# CC27x0 register map
File version: 1.0
CPU: CM4 r0p4, little endian, no MPU, no FPU, VTOR, 3 interrupt priority bits
Registers are 32-bit, read-write, reset 0x0 unless marked. A register's access mark holds for its fields unless they carry their own. Offsets are from the block's base; [hi:lo] are bit positions; {n}, {i} and the like mark numbered series; 'fields as' and 'values as' point back to an identical list.

## LRFDMDM (part 1 of 2)
Base 0x40082000
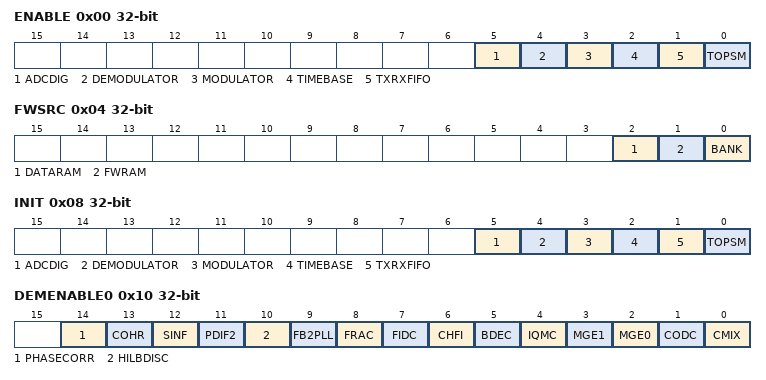
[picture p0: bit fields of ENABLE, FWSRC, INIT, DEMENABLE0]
0x00 ENABLE — Internal. Only to be used through TI provided API.
  [all] fields
    1=EN (Internal. Only to be used through TI provided API.); 0=DIS (Internal. Only to be used through TI provided API.)
  [5] ADCDIG — Internal. Only to be used through TI provided API.
  [4] DEMODULATOR — Internal. Only to be used through TI provided API.
  [3] MODULATOR — Internal. Only to be used through TI provided API.
  [2] TIMEBASE — Internal. Only to be used through TI provided API.
  [1] TXRXFIFO — Internal. Only to be used through TI provided API.
  [0] TOPSM — Internal. Only to be used through TI provided API.
0x04 FWSRC — Internal. Only to be used through TI provided API.
  [2] DATARAM — Internal. Only to be used through TI provided API.
    1=S2RRAM (Internal. Only to be used through TI provided API.); 0=MDMRAM (Internal. Only to be used through TI provided API.)
  [1] FWRAM — Internal. Only to be used through TI provided API.
    values as DATARAM
  [0] BANK — Internal. Only to be used through TI provided API.
    1=ONE (Internal. Only to be used through TI provided API.); 0=ZERO (Internal. Only to be used through TI provided API.)
0x08 INIT wo — Internal. Only to be used through TI provided API.
  [all] fields
    1=RESET (Internal. Only to be used through TI provided API.); 0=NO_EFFECT (Internal. Only to be used through TI provided API.)
  [5] ADCDIG — Internal. Only to be used through TI provided API.
  [4] DEMODULATOR — Internal. Only to be used through TI provided API.
  [3] MODULATOR — Internal. Only to be used through TI provided API.
  [2] TIMEBASE — Internal. Only to be used through TI provided API.
  [1] TXRXFIFO — Internal. Only to be used through TI provided API.
  [0] TOPSM — Internal. Only to be used through TI provided API.
0x10 DEMENABLE0 — Internal. Only to be used through TI provided API.
  [14] PHASECORR — Internal. Only to be used through TI provided API.
  [13] COHR — Internal. Only to be used through TI provided API.
  [12] SINF — Internal. Only to be used through TI provided API.
  [11] PDIF2 — Internal. Only to be used through TI provided API.
  [10] HILBDISC — Internal. Only to be used through TI provided API.
  [9] FB2PLL — Internal. Only to be used through TI provided API.
  [8] FRAC — Internal. Only to be used through TI provided API.
    values as the fields of ENABLE
  [7] FIDC — Internal. Only to be used through TI provided API.
    values as the fields of ENABLE
  [6] CHFI — Internal. Only to be used through TI provided API.
    values as the fields of ENABLE
  [5] BDEC — Internal. Only to be used through TI provided API.
    values as the fields of ENABLE
  [4] IQMC — Internal. Only to be used through TI provided API.
    values as the fields of ENABLE
  [3] MGE1 — Internal. Only to be used through TI provided API.
    values as the fields of ENABLE
  [2] MGE0 — Internal. Only to be used through TI provided API.
    values as the fields of ENABLE
  [1] CODC — Internal. Only to be used through TI provided API.
    values as the fields of ENABLE
  [0] CMIX — Internal. Only to be used through TI provided API.
    values as the fields of ENABLE
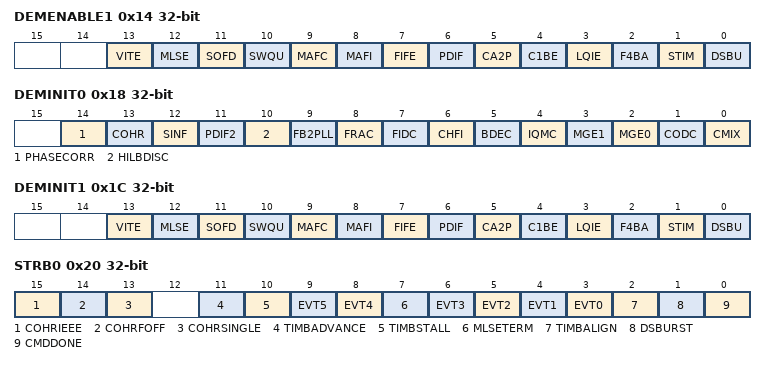
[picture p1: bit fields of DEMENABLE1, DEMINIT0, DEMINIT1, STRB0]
0x14 DEMENABLE1 — Internal. Only to be used through TI provided API.
  [all] fields
    values as the fields of ENABLE
  [13] VITE — Internal. Only to be used through TI provided API.
  [12] MLSE — Internal. Only to be used through TI provided API.
  [11] SOFD — Internal. Only to be used through TI provided API.
  [10] SWQU — Internal. Only to be used through TI provided API.
  [9] MAFC — Internal. Only to be used through TI provided API.
  [8] MAFI — Internal. Only to be used through TI provided API.
  [7] FIFE — Internal. Only to be used through TI provided API.
  [6] PDIF — Internal. Only to be used through TI provided API.
  [5] CA2P — Internal. Only to be used through TI provided API.
  [4] C1BE — Internal. Only to be used through TI provided API.
  [3] LQIE — Internal. Only to be used through TI provided API.
  [2] F4BA — Internal. Only to be used through TI provided API.
  [1] STIM — Internal. Only to be used through TI provided API.
  [0] DSBU — Internal. Only to be used through TI provided API.
0x18 DEMINIT0 wo — Internal. Only to be used through TI provided API.
  [14] PHASECORR — Internal. Only to be used through TI provided API.
  [13] COHR — Internal. Only to be used through TI provided API.
  [12] SINF — Internal. Only to be used through TI provided API.
  [11] PDIF2 — Internal. Only to be used through TI provided API.
  [10] HILBDISC — Internal. Only to be used through TI provided API.
  [9] FB2PLL — Internal. Only to be used through TI provided API.
  [8] FRAC — Internal. Only to be used through TI provided API.
    values as the fields of INIT
  [7] FIDC — Internal. Only to be used through TI provided API.
    values as the fields of INIT
  [6] CHFI — Internal. Only to be used through TI provided API.
    values as the fields of INIT
  [5] BDEC — Internal. Only to be used through TI provided API.
    values as the fields of INIT
  [4] IQMC — Internal. Only to be used through TI provided API.
    values as the fields of INIT
  [3] MGE1 — Internal. Only to be used through TI provided API.
    values as the fields of INIT
  [2] MGE0 — Internal. Only to be used through TI provided API.
    values as the fields of INIT
  [1] CODC — Internal. Only to be used through TI provided API.
    values as the fields of INIT
  [0] CMIX — Internal. Only to be used through TI provided API.
    values as the fields of INIT
0x1C DEMINIT1 wo — Internal. Only to be used through TI provided API.
  [all] fields
    values as the fields of INIT
  [13] VITE — Internal. Only to be used through TI provided API.
  [12] MLSE — Internal. Only to be used through TI provided API.
  [11] SOFD — Internal. Only to be used through TI provided API.
  [10] SWQU — Internal. Only to be used through TI provided API.
  [9] MAFC — Internal. Only to be used through TI provided API.
  [8] MAFI — Internal. Only to be used through TI provided API.
  [7] FIFE — Internal. Only to be used through TI provided API.
  [6] PDIF — Internal. Only to be used through TI provided API.
  [5] CA2P — Internal. Only to be used through TI provided API.
  [4] C1BE — Internal. Only to be used through TI provided API.
  [3] LQIE — Internal. Only to be used through TI provided API.
  [2] F4BA — Internal. Only to be used through TI provided API.
  [1] STIM — Internal. Only to be used through TI provided API.
  [0] DSBU — Internal. Only to be used through TI provided API.
0x20 STRB0 wo — Internal. Only to be used through TI provided API.
  [15] COHRIEEE — Internal. Only to be used through TI provided API.
  [14] COHRFOFF — Internal. Only to be used through TI provided API.
  [13] COHRSINGLE — Internal. Only to be used through TI provided API.
  [11] TIMBADVANCE — Internal. Only to be used through TI provided API.
    1=ON (Internal. Only to be used through TI provided API.); 0=NO_EFFECT (Internal. Only to be used through TI provided API.)
  [10] TIMBSTALL — Internal. Only to be used through TI provided API.
    values as TIMBADVANCE
  [9] EVT5 — Internal. Only to be used through TI provided API.
    values as FWSRC.BANK
  [8] EVT4 — Internal. Only to be used through TI provided API.
    values as FWSRC.BANK
  [7] MLSETERM — Internal. Only to be used through TI provided API.
    1=ON (Internal. Only to be used through TI provided API.); 0=OFF (Internal. Only to be used through TI provided API.)
  [n+3] EVT{n} (n=0..3) — Internal. Only to be used through TI provided API.
    values as FWSRC.BANK
  [2] TIMBALIGN — Internal. Only to be used through TI provided API.
    values as TIMBADVANCE
  [1] DSBURST — Internal. Only to be used through TI provided API.
    1=RESTART (Internal. Only to be used through TI provided API.); 0=NO_EFFECT (Internal. Only to be used through TI provided API.)
  [0] CMDDONE — Internal. Only to be used through TI provided API.
    1=YES (Internal. Only to be used through TI provided API.); 0=NO (Internal. Only to be used through TI provided API.)
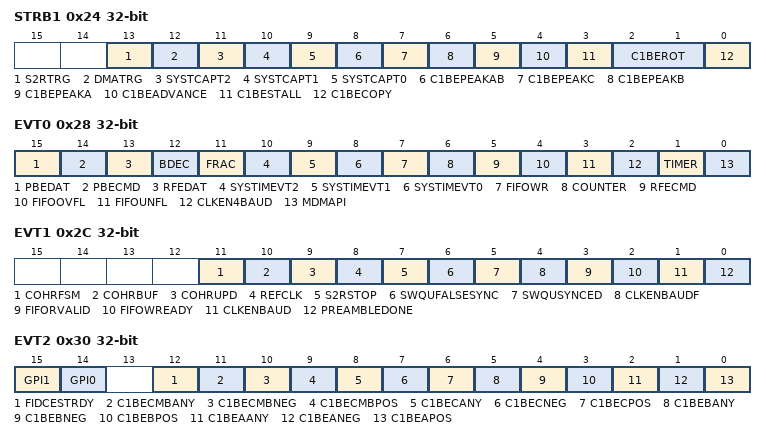
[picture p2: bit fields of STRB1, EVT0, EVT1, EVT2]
0x24 STRB1 wo — Internal. Only to be used through TI provided API.
  [13] S2RTRG — Internal. Only to be used through TI provided API.
    values as FWSRC.BANK
  [12] DMATRG — Internal. Only to be used through TI provided API.
    values as FWSRC.BANK
  [11] SYSTCAPT2 — Internal. Only to be used through TI provided API.
    values as FWSRC.BANK
  [10] SYSTCAPT1 — Internal. Only to be used through TI provided API.
    values as FWSRC.BANK
  [9] SYSTCAPT0 — Internal. Only to be used through TI provided API.
    values as FWSRC.BANK
  [8] C1BEPEAKAB — Internal. Only to be used through TI provided API.
    values as FWSRC.BANK
  [7] C1BEPEAKC — Internal. Only to be used through TI provided API.
    values as FWSRC.BANK
  [6] C1BEPEAKB — Internal. Only to be used through TI provided API.
    values as FWSRC.BANK
  [5] C1BEPEAKA — Internal. Only to be used through TI provided API.
    values as FWSRC.BANK
  [4] C1BEADVANCE — Internal. Only to be used through TI provided API.
    values as FWSRC.BANK
  [3] C1BESTALL — Internal. Only to be used through TI provided API.
    values as FWSRC.BANK
  [2:1] C1BEROT — Internal. Only to be used through TI provided API.
    3=ROT16R (Internal. Only to be used through TI provided API.); 2=ROT1L (Internal. Only to be used through TI provided API.); 1=ROT1R (Internal. Only to be used through TI provided API.); 0=ROT0 (Internal. Only to be used through TI provided API.)
  [0] C1BECOPY — Internal. Only to be used through TI provided API.
    values as FWSRC.BANK
0x28 EVT0 ro — Internal. Only to be used through TI provided API.
  [all] fields
    values as FWSRC.BANK
  [15] PBEDAT — Internal. Only to be used through TI provided API.
  [14] PBECMD — Internal. Only to be used through TI provided API.
  [13] RFEDAT — Internal. Only to be used through TI provided API.
  [12] BDEC — Internal. Only to be used through TI provided API.
  [11] FRAC — Internal. Only to be used through TI provided API.
  [10] SYSTIMEVT2 — Internal. Only to be used through TI provided API.
  [9] SYSTIMEVT1 — Internal. Only to be used through TI provided API.
  [8] SYSTIMEVT0 — Internal. Only to be used through TI provided API.
  [7] FIFOWR — Internal. Only to be used through TI provided API.
  [6] COUNTER — Internal. Only to be used through TI provided API.
  [5] RFECMD — Internal. Only to be used through TI provided API.
  [4] FIFOOVFL — Internal. Only to be used through TI provided API.
  [3] FIFOUNFL — Internal. Only to be used through TI provided API.
  [2] CLKEN4BAUD — Internal. Only to be used through TI provided API.
  [1] TIMER — Internal. Only to be used through TI provided API.
  [0] MDMAPI — Internal. Only to be used through TI provided API.
0x2C EVT1 ro — Internal. Only to be used through TI provided API.
  [11] COHRFSM — Internal. Only to be used through TI provided API.
  [10] COHRBUF — Internal. Only to be used through TI provided API.
  [9] COHRUPD — Internal. Only to be used through TI provided API.
  [8] REFCLK — Internal. Only to be used through TI provided API.
    values as FWSRC.BANK
  [7] S2RSTOP — Internal. Only to be used through TI provided API.
    values as FWSRC.BANK
  [6] SWQUFALSESYNC — Internal. Only to be used through TI provided API.
    values as FWSRC.BANK
  [5] SWQUSYNCED — Internal. Only to be used through TI provided API.
    values as FWSRC.BANK
  [4] CLKENBAUDF — Internal. Only to be used through TI provided API.
    values as FWSRC.BANK
  [3] FIFORVALID — Internal. Only to be used through TI provided API.
    values as FWSRC.BANK
  [2] FIFOWREADY — Internal. Only to be used through TI provided API.
    values as FWSRC.BANK
  [1] CLKENBAUD — Internal. Only to be used through TI provided API.
    values as FWSRC.BANK
  [0] PREAMBLEDONE — Internal. Only to be used through TI provided API.
    values as FWSRC.BANK
0x30 EVT2 ro — Internal. Only to be used through TI provided API.
  [all] fields
    values as FWSRC.BANK
  [15] GPI1 — Internal. Only to be used through TI provided API.
  [14] GPI0 — Internal. Only to be used through TI provided API.
  [12] FIDCESTRDY — Internal. Only to be used through TI provided API.
  [11] C1BECMBANY — Internal. Only to be used through TI provided API.
  [10] C1BECMBNEG — Internal. Only to be used through TI provided API.
  [9] C1BECMBPOS — Internal. Only to be used through TI provided API.
  [8] C1BECANY — Internal. Only to be used through TI provided API.
  [7] C1BECNEG — Internal. Only to be used through TI provided API.
  [6] C1BECPOS — Internal. Only to be used through TI provided API.
  [5] C1BEBANY — Internal. Only to be used through TI provided API.
  [4] C1BEBNEG — Internal. Only to be used through TI provided API.
  [3] C1BEBPOS — Internal. Only to be used through TI provided API.
  [2] C1BEAANY — Internal. Only to be used through TI provided API.
  [1] C1BEANEG — Internal. Only to be used through TI provided API.
  [0] C1BEAPOS — Internal. Only to be used through TI provided API.
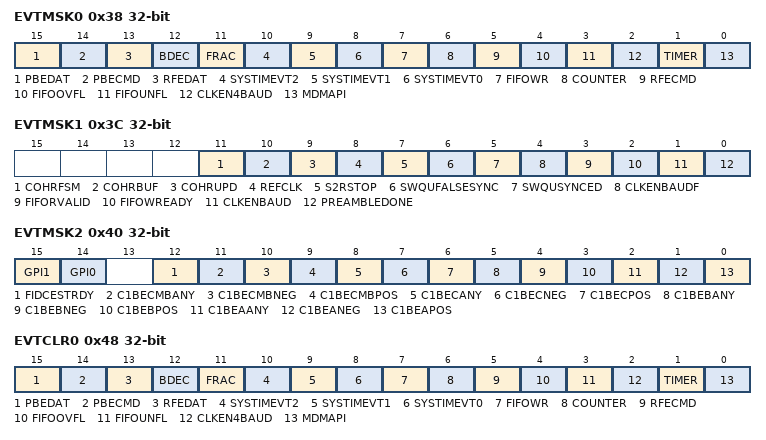
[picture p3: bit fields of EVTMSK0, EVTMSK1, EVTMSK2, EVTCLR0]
0x38 EVTMSK0 — Internal. Only to be used through TI provided API.
  [all] fields
    values as the fields of ENABLE
  [15] PBEDAT — Internal. Only to be used through TI provided API.
  [14] PBECMD — Internal. Only to be used through TI provided API.
  [13] RFEDAT — Internal. Only to be used through TI provided API.
  [12] BDEC — Internal. Only to be used through TI provided API.
  [11] FRAC — Internal. Only to be used through TI provided API.
  [10] SYSTIMEVT2 — Internal. Only to be used through TI provided API.
  [9] SYSTIMEVT1 — Internal. Only to be used through TI provided API.
  [8] SYSTIMEVT0 — Internal. Only to be used through TI provided API.
  [7] FIFOWR — Internal. Only to be used through TI provided API.
  [6] COUNTER — Internal. Only to be used through TI provided API.
  [5] RFECMD — Internal. Only to be used through TI provided API.
  [4] FIFOOVFL — Internal. Only to be used through TI provided API.
  [3] FIFOUNFL — Internal. Only to be used through TI provided API.
  [2] CLKEN4BAUD — Internal. Only to be used through TI provided API.
  [1] TIMER — Internal. Only to be used through TI provided API.
  [0] MDMAPI — Internal. Only to be used through TI provided API.
0x3C EVTMSK1 — Internal. Only to be used through TI provided API.
  [11] COHRFSM — Internal. Only to be used through TI provided API.
  [10] COHRBUF — Internal. Only to be used through TI provided API.
  [9] COHRUPD — Internal. Only to be used through TI provided API.
  [8] REFCLK — Internal. Only to be used through TI provided API.
    values as the fields of ENABLE
  [7] S2RSTOP — Internal. Only to be used through TI provided API.
    values as the fields of ENABLE
  [6] SWQUFALSESYNC — Internal. Only to be used through TI provided API.
    values as the fields of ENABLE
  [5] SWQUSYNCED — Internal. Only to be used through TI provided API.
    values as the fields of ENABLE
  [4] CLKENBAUDF — Internal. Only to be used through TI provided API.
    values as the fields of ENABLE
  [3] FIFORVALID — Internal. Only to be used through TI provided API.
    values as the fields of ENABLE
  [2] FIFOWREADY — Internal. Only to be used through TI provided API.
    values as the fields of ENABLE
  [1] CLKENBAUD — Internal. Only to be used through TI provided API.
    values as the fields of ENABLE
  [0] PREAMBLEDONE — Internal. Only to be used through TI provided API.
    values as the fields of ENABLE
0x40 EVTMSK2 — Internal. Only to be used through TI provided API.
  [all] fields
    values as the fields of ENABLE
  [15] GPI1 — Internal. Only to be used through TI provided API.
  [14] GPI0 — Internal. Only to be used through TI provided API.
  [12] FIDCESTRDY — Internal. Only to be used through TI provided API.
  [11] C1BECMBANY — Internal. Only to be used through TI provided API.
  [10] C1BECMBNEG — Internal. Only to be used through TI provided API.
  [9] C1BECMBPOS — Internal. Only to be used through TI provided API.
  [8] C1BECANY — Internal. Only to be used through TI provided API.
  [7] C1BECNEG — Internal. Only to be used through TI provided API.
  [6] C1BECPOS — Internal. Only to be used through TI provided API.
  [5] C1BEBANY — Internal. Only to be used through TI provided API.
  [4] C1BEBNEG — Internal. Only to be used through TI provided API.
  [3] C1BEBPOS — Internal. Only to be used through TI provided API.
  [2] C1BEAANY — Internal. Only to be used through TI provided API.
  [1] C1BEANEG — Internal. Only to be used through TI provided API.
  [0] C1BEAPOS — Internal. Only to be used through TI provided API.
0x48 EVTCLR0 wo — Internal. Only to be used through TI provided API.
  [all] fields
    1=CLEAR (Internal. Only to be used through TI provided API.); 0=RETAIN (Internal. Only to be used through TI provided API.)
  [15] PBEDAT — Internal. Only to be used through TI provided API.
  [14] PBECMD — Internal. Only to be used through TI provided API.
  [13] RFEDAT — Internal. Only to be used through TI provided API.
  [12] BDEC — Internal. Only to be used through TI provided API.
  [11] FRAC — Internal. Only to be used through TI provided API.
  [10] SYSTIMEVT2 — Internal. Only to be used through TI provided API.
  [9] SYSTIMEVT1 — Internal. Only to be used through TI provided API.
  [8] SYSTIMEVT0 — Internal. Only to be used through TI provided API.
  [7] FIFOWR — Internal. Only to be used through TI provided API.
  [6] COUNTER — Internal. Only to be used through TI provided API.
  [5] RFECMD — Internal. Only to be used through TI provided API.
  [4] FIFOOVFL — Internal. Only to be used through TI provided API.
  [3] FIFOUNFL — Internal. Only to be used through TI provided API.
  [2] CLKEN4BAUD — Internal. Only to be used through TI provided API.
  [1] TIMER — Internal. Only to be used through TI provided API.
  [0] MDMAPI — Internal. Only to be used through TI provided API.
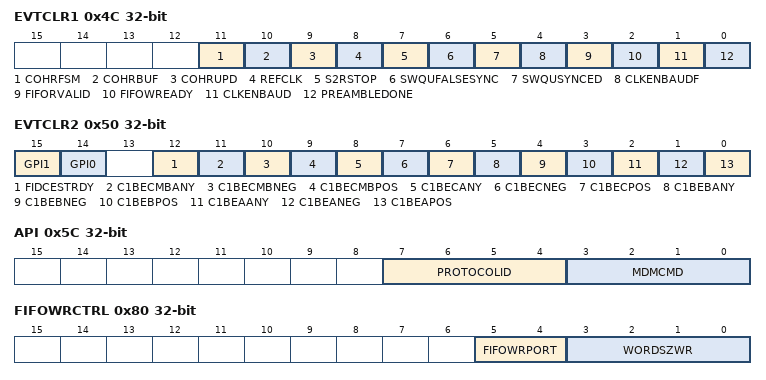
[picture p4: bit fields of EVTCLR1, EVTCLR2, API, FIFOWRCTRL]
0x4C EVTCLR1 wo — Internal. Only to be used through TI provided API.
  [11] COHRFSM — Internal. Only to be used through TI provided API.
  [10] COHRBUF — Internal. Only to be used through TI provided API.
  [9] COHRUPD — Internal. Only to be used through TI provided API.
  [8] REFCLK — Internal. Only to be used through TI provided API.
    values as the fields of EVTCLR0
  [7] S2RSTOP — Internal. Only to be used through TI provided API.
    values as the fields of EVTCLR0
  [6] SWQUFALSESYNC — Internal. Only to be used through TI provided API.
    values as the fields of EVTCLR0
  [5] SWQUSYNCED — Internal. Only to be used through TI provided API.
    values as the fields of EVTCLR0
  [4] CLKENBAUDF — Internal. Only to be used through TI provided API.
    values as the fields of EVTCLR0
  [3] FIFORVALID — Internal. Only to be used through TI provided API.
    values as the fields of EVTCLR0
  [2] FIFOWREADY — Internal. Only to be used through TI provided API.
    values as the fields of EVTCLR0
  [1] CLKENBAUD — Internal. Only to be used through TI provided API.
    values as the fields of EVTCLR0
  [0] PREAMBLEDONE — Internal. Only to be used through TI provided API.
    values as the fields of EVTCLR0
0x50 EVTCLR2 wo — Internal. Only to be used through TI provided API.
  [all] fields
    values as the fields of EVTCLR0
  [15] GPI1 — Internal. Only to be used through TI provided API.
  [14] GPI0 — Internal. Only to be used through TI provided API.
  [12] FIDCESTRDY — Internal. Only to be used through TI provided API.
  [11] C1BECMBANY — Internal. Only to be used through TI provided API.
  [10] C1BECMBNEG — Internal. Only to be used through TI provided API.
  [9] C1BECMBPOS — Internal. Only to be used through TI provided API.
  [8] C1BECANY — Internal. Only to be used through TI provided API.
  [7] C1BECNEG — Internal. Only to be used through TI provided API.
  [6] C1BECPOS — Internal. Only to be used through TI provided API.
  [5] C1BEBANY — Internal. Only to be used through TI provided API.
  [4] C1BEBNEG — Internal. Only to be used through TI provided API.
  [3] C1BEBPOS — Internal. Only to be used through TI provided API.
  [2] C1BEAANY — Internal. Only to be used through TI provided API.
  [1] C1BEANEG — Internal. Only to be used through TI provided API.
  [0] C1BEAPOS — Internal. Only to be used through TI provided API.
0x58 PDREQ — Internal. Only to be used through TI provided API.
  [0] TOPSMPDREQ
    values as STRB0.MLSETERM
0x5C API ro — Internal. Only to be used through TI provided API.
  [7:4] PROTOCOLID — Internal. Only to be used through TI provided API.
    15=ALLONES (Internal. Only to be used through TI provided API.); 0=ALLZEROS (Internal. Only to be used through TI provided API.)
  [3:0] MDMCMD — Internal. Only to be used through TI provided API.
    values as PROTOCOLID
{0x60+4i} CMDPAR{i} ro (i=0..2) — Internal. Only to be used through TI provided API.
  [15:0] VAL
    0xFFFF=ALLONES (Internal. Only to be used through TI provided API.); 0=ALLZEROS (Internal. Only to be used through TI provided API.)
0x6C MSGBOX — Internal. Only to be used through TI provided API.
  [7:0] VAL
    255=ALLONES (Internal. Only to be used through TI provided API.); 0=ALLZEROS (Internal. Only to be used through TI provided API.)
0x70 FREQ — Internal. Only to be used through TI provided API.
  [15:0] OFFSET
    values as CMDPAR0.VAL
0x74 FIFOWR — Internal. Only to be used through TI provided API.
  [15:0] PAYLOADIN
    values as CMDPAR0.VAL
0x78 FIFORD ro — Internal. Only to be used through TI provided API.
  [15:0] PAYLOADOUT
    values as CMDPAR0.VAL
0x80 FIFOWRCTRL — Internal. Only to be used through TI provided API.
  [5:4] FIFOWRPORT — Internal. Only to be used through TI provided API.
    2=PBE (Internal. Only to be used through TI provided API.); 1=MODEM (Internal. Only to be used through TI provided API.); 0=MDMFIFOWR (Internal. Only to be used through TI provided API.)
  [3:0] WORDSZWR — Internal. Only to be used through TI provided API.
    {v}=BITS{v+1} (Internal. Only to be used through TI provided API.) (v=0..15)
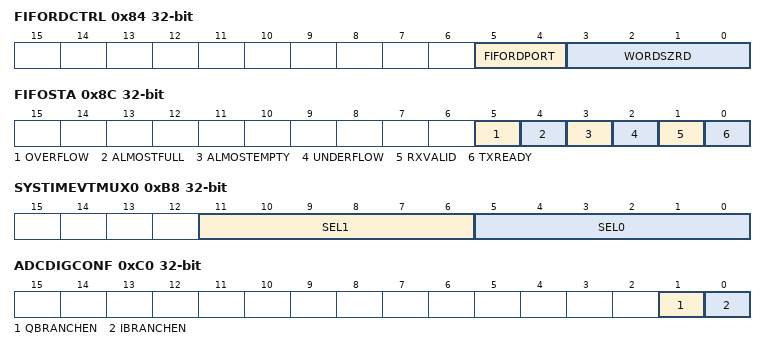
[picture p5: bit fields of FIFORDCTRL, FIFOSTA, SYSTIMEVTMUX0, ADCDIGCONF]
0x84 FIFORDCTRL — Internal. Only to be used through TI provided API.
  [5:4] FIFORDPORT — Internal. Only to be used through TI provided API.
    2=PBE (Internal. Only to be used through TI provided API.); 1=MODEM (Internal. Only to be used through TI provided API.); 0=MDMFIFORD (Internal. Only to be used through TI provided API.)
  [3:0] WORDSZRD — Internal. Only to be used through TI provided API.
    values as FIFOWRCTRL.WORDSZWR
0x88 PBEDATOUT1 — Internal. Only to be used through TI provided API.
  fields as CMDPAR0
0x8C FIFOSTA ro — Internal. Only to be used through TI provided API.
  [all] fields
    values as FWSRC.BANK
  [5] OVERFLOW — Internal. Only to be used through TI provided API.
  [4] ALMOSTFULL — Internal. Only to be used through TI provided API.
  [3] ALMOSTEMPTY — Internal. Only to be used through TI provided API.
  [2] UNDERFLOW — Internal. Only to be used through TI provided API.
  [1] RXVALID — Internal. Only to be used through TI provided API.
  [0] TXREADY — Internal. Only to be used through TI provided API.
0x90 RFEDATOUT0 — Internal. Only to be used through TI provided API.
  fields as CMDPAR0
0x94 RFEDATIN0 ro — Internal. Only to be used through TI provided API.
  fields as CMDPAR0
0x98 RFECMDOUT — Internal. Only to be used through TI provided API.
  [3:0] VAL
    values as API.PROTOCOLID
0x9C RFECMDIN ro — Internal. Only to be used through TI provided API.
  fields as RFECMDOUT
0xA0 PBEDATOUT0 — Internal. Only to be used through TI provided API.
  fields as CMDPAR0
0xA4 PBEDATIN0 ro — Internal. Only to be used through TI provided API.
  fields as CMDPAR0
0xA8 PBECMDOUT — Internal. Only to be used through TI provided API.
  fields as RFECMDOUT
0xAC PBECMDIN ro — Internal. Only to be used through TI provided API.
  fields as RFECMDOUT
0xB0 LQIEST — Internal. Only to be used through TI provided API.
  fields as MSGBOX
0xB4 PBEEVTMUX — Internal. Only to be used through TI provided API.
  [5:0] SEL
    63=ALLONES (Internal. Only to be used through TI provided API.); 0=ALLZEROS (Internal. Only to be used through TI provided API.)
0xB8 SYSTIMEVTMUX0 — Internal. Only to be used through TI provided API.
  [11:6] SEL1 — Internal. Only to be used through TI provided API.
    values as PBEEVTMUX.SEL
  [5:0] SEL0 — Internal. Only to be used through TI provided API.
    values as PBEEVTMUX.SEL
0xBC SYSTIMEVTMUX1 — Internal. Only to be used through TI provided API.
  [5:0] SEL2
    values as PBEEVTMUX.SEL
0xC0 ADCDIGCONF — Internal. Only to be used through TI provided API.
  [1] QBRANCHEN — Internal. Only to be used through TI provided API.
    values as STRB0.MLSETERM
  [0] IBRANCHEN — Internal. Only to be used through TI provided API.
    values as STRB0.MLSETERM
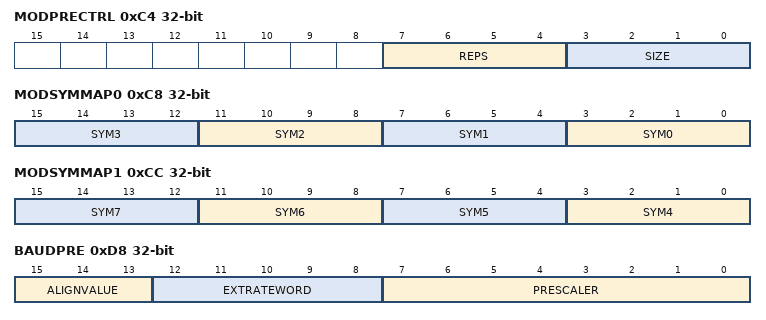
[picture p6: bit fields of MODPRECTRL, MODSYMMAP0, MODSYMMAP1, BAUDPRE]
0xC4 MODPRECTRL — Internal. Only to be used through TI provided API.
  [7:4] REPS — Internal. Only to be used through TI provided API.
    {v}=Internal. Only to be used through TI provided API. (v=0..15)
  [3:0] SIZE — Internal. Only to be used through TI provided API.
    15=BITS16 (Internal. Only to be used through TI provided API.); 7=BITS8 (Internal. Only to be used through TI provided API.); 3=BITS4 (Internal. Only to be used through TI provided API.)
0xC8 MODSYMMAP0 — Internal. Only to be used through TI provided API.
  [all] fields
    values as API.PROTOCOLID
  [4n+3:4n] SYM{n} (n=0..3) — Internal. Only to be used through TI provided API.
0xCC MODSYMMAP1 — Internal. Only to be used through TI provided API.
  [all] fields
    values as API.PROTOCOLID
  [4n-13:4n-16] SYM{n} (n=4..7) — Internal. Only to be used through TI provided API.
0xD0 MODSOFTTX — Internal. Only to be used through TI provided API.
  [3:0] SOFTSYMBOL
    values as API.PROTOCOLID
0xD4 BAUD — Internal. Only to be used through TI provided API.
  [15:0] RATEWORD
    values as CMDPAR0.VAL
0xD8 BAUDPRE — Internal. Only to be used through TI provided API.
  [15:13] ALIGNVALUE — Internal. Only to be used through TI provided API.
    7=ALLONES (Internal. Only to be used through TI provided API.); 0=ALLZEROS (Internal. Only to be used through TI provided API.)
  [12:8] EXTRATEWORD — Internal. Only to be used through TI provided API.
    31=ALLONES (Internal. Only to be used through TI provided API.); 0=ALLZEROS (Internal. Only to be used through TI provided API.)
  [7:0] PRESCALER — Internal. Only to be used through TI provided API.
    values as MSGBOX.VAL
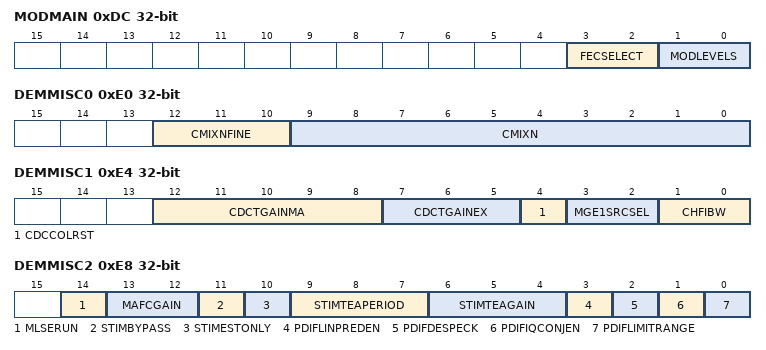
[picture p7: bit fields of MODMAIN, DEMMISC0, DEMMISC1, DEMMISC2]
0xDC MODMAIN — Internal. Only to be used through TI provided API.
  [3:2] FECSELECT — Internal. Only to be used through TI provided API.
    3=BLR (Internal. Only to be used through TI provided API.); 2=RESERVED (Internal. Only to be used through TI provided API.); 1=IEEE15_4 (Internal. Only to be used through TI provided API.); 0=NOSEL (Internal. Only to be used through TI provided API.)
  [1:0] MODLEVELS — Internal. Only to be used through TI provided API.
    2=LVL8 (Internal. Only to be used through TI provided API.); 1=LVL4 (Internal. Only to be used through TI provided API.); 0=LVL2 (Internal. Only to be used through TI provided API.)
0xE0 DEMMISC0 — Internal. Only to be used through TI provided API.
  [12:10] CMIXNFINE — Internal. Only to be used through TI provided API.
  [9:0] CMIXN — Internal. Only to be used through TI provided API.
    0x3FF=ALLONES (Internal. Only to be used through TI provided API.); 0=ALLZEROS (Internal. Only to be used through TI provided API.)
0xE4 DEMMISC1 — Internal. Only to be used through TI provided API.
  [12:8] CDCTGAINMA — Internal. Only to be used through TI provided API.
    values as BAUDPRE.EXTRATEWORD
  [7:5] CDCTGAINEX — Internal. Only to be used through TI provided API.
    values as BAUDPRE.ALIGNVALUE
  [4] CDCCOLRST — Internal. Only to be used through TI provided API.
    values as the fields of ENABLE
  [3:2] MGE1SRCSEL — Internal. Only to be used through TI provided API.
    2=CHFI (Internal. Only to be used through TI provided API.); 1=FEXB1 (Internal. Only to be used through TI provided API.); 0=FIDC (Internal. Only to be used through TI provided API.)
  [1:0] CHFIBW — Internal. Only to be used through TI provided API.
    3=BW0_29 (Internal. Only to be used through TI provided API.); 2=BW0_41667 (Internal. Only to be used through TI provided API.); 1=BW0_3333 (Internal. Only to be used through TI provided API.); 0=BW0_5 (Internal. Only to be used through TI provided API.)
0xE8 DEMMISC2 — Internal. Only to be used through TI provided API.
  [14] MLSERUN — Internal. Only to be used through TI provided API.
    values as the fields of ENABLE
  [13:12] MAFCGAIN — Internal. Only to be used through TI provided API.
    3=ALLONES (Internal. Only to be used through TI provided API.); 0=ALLZEROS (Internal. Only to be used through TI provided API.)
  [11] STIMBYPASS — Internal. Only to be used through TI provided API.
    values as the fields of ENABLE
  [10] STIMESTONLY — Internal. Only to be used through TI provided API.
    values as the fields of ENABLE
  [9:7] STIMTEAPERIOD — Internal. Only to be used through TI provided API.
    5=SYM128 (Internal. Only to be used through TI provided API.); 4=SYM64 (Internal. Only to be used through TI provided API.); 3=SYM32 (Internal. Only to be used through TI provided API.); 2=SYM16 (Internal. Only to be used through TI provided API.); 1=SYM8 (Internal. Only to be used through TI provided API.); 0=SYM4 (Internal. Only to be used through TI provided API.)
  [6:4] STIMTEAGAIN — Internal. Only to be used through TI provided API.
    7=DIV4 (Internal. Only to be used through TI provided API.); 6=DIV8 (Internal. Only to be used through TI provided API.); 5=DIV16 (Internal. Only to be used through TI provided API.); 4=DIV32 (Internal. Only to be used through TI provided API.); 3=DIV64 (Internal. Only to be used through TI provided API.); 2=DIV128 (Internal. Only to be used through TI provided API.); 1=DIV256 (Internal. Only to be used through TI provided API.); 0=DIV512 (Internal. Only to be used through TI provided API.)
  [3] PDIFLINPREDEN — Internal. Only to be used through TI provided API.
    values as STRB0.MLSETERM
  [2] PDIFDESPECK — Internal. Only to be used through TI provided API.
    values as the fields of ENABLE
  [1] PDIFIQCONJEN — Internal. Only to be used through TI provided API.
    values as STRB0.MLSETERM
  [0] PDIFLIMITRANGE — Internal. Only to be used through TI provided API.
    values as the fields of ENABLE
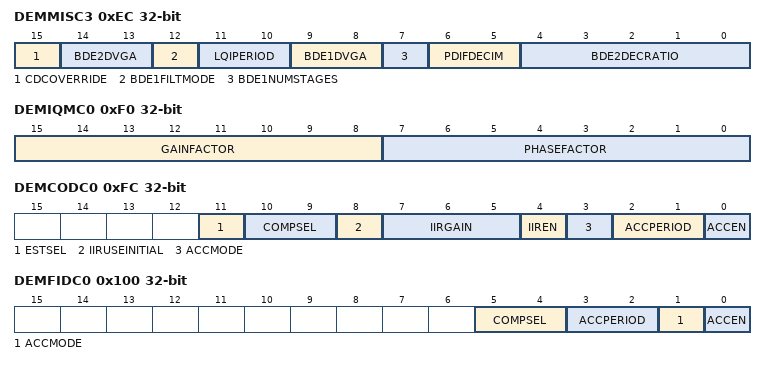
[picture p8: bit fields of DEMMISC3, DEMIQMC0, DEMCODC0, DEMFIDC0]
0xEC DEMMISC3 — Internal. Only to be used through TI provided API.
  [15] CDCOVERRIDE — Internal. Only to be used through TI provided API.
    3=GAIN8 (Internal. Only to be used through TI provided API.); 2=GAIN4 (Internal. Only to be used through TI provided API.); 1=GAIN2 (Internal. Only to be used through TI provided API.); 0=GAIN1 (Internal. Only to be used through TI provided API.)
  [14:13] BDE2DVGA — Internal. Only to be used through TI provided API.
    values as CDCOVERRIDE
  [12] BDE1FILTMODE — Internal. Only to be used through TI provided API.
    1=DIV2 (Internal. Only to be used through TI provided API.); 0=DIV1 (Internal. Only to be used through TI provided API.)
  [11:10] LQIPERIOD — Internal. Only to be used through TI provided API.
    3=SYM1024 (Internal. Only to be used through TI provided API.); 2=SYM256 (Internal. Only to be used through TI provided API.); 1=SYM64 (Internal. Only to be used through TI provided API.); 0=SYM16 (Internal. Only to be used through TI provided API.)
  [9:8] BDE1DVGA — Internal. Only to be used through TI provided API.
    values as CDCOVERRIDE
  [7] BDE1NUMSTAGES — Internal. Only to be used through TI provided API.
    values as BDE1FILTMODE
  [6:5] PDIFDECIM — Internal. Only to be used through TI provided API.
    2=DIV4 (Internal. Only to be used through TI provided API.); 1=DIV2 (Internal. Only to be used through TI provided API.); 0=DIV1 (Internal. Only to be used through TI provided API.)
  [4:0] BDE2DECRATIO — Internal. Only to be used through TI provided API.
    3=DIV8 (Internal. Only to be used through TI provided API.); 2=DIV4 (Internal. Only to be used through TI provided API.); 1=DIV2 (Internal. Only to be used through TI provided API.); 0=DIV1 (Internal. Only to be used through TI provided API.)
0xF0 DEMIQMC0 — Internal. Only to be used through TI provided API.
  [15:8] GAINFACTOR — Internal. Only to be used through TI provided API.
    values as MSGBOX.VAL
  [7:0] PHASEFACTOR — Internal. Only to be used through TI provided API.
    values as MSGBOX.VAL
0xF4 DEMDSBU — Internal. Only to be used through TI provided API.
  [8:0] DSBUDELAY
    values as MSGBOX.VAL
0xF8 DEMDSBU2 — Internal. Only to be used through TI provided API.
  [8:0] DSBUAVGLENGTH
0xFC DEMCODC0 — Internal. Only to be used through TI provided API.
  [11] ESTSEL — Internal. Only to be used through TI provided API.
    1=IIR (Internal. Only to be used through TI provided API.); 0=ACC (Internal. Only to be used through TI provided API.)
  [10:9] COMPSEL — Internal. Only to be used through TI provided API.
    3=IIR (Internal. Only to be used through TI provided API.); 2=ACC (Internal. Only to be used through TI provided API.); 0=MANUAL (Internal. Only to be used through TI provided API.)
  [8] IIRUSEINITIAL — Internal. Only to be used through TI provided API.
    values as the fields of ENABLE
  [7:5] IIRGAIN — Internal. Only to be used through TI provided API.
    7=DIV1024 (Internal. Only to be used through TI provided API.); 6=DIV512 (Internal. Only to be used through TI provided API.); 5=DIV256 (Internal. Only to be used through TI provided API.); 4=DIV128 (Internal. Only to be used through TI provided API.); 3=DIV64 (Internal. Only to be used through TI provided API.); 2=DIV32 (Internal. Only to be used through TI provided API.); 1=DIV16 (Internal. Only to be used through TI provided API.); 0=OFF (Internal. Only to be used through TI provided API.)
  [4] IIREN — Internal. Only to be used through TI provided API.
    values as STRB0.MLSETERM
  [3] ACCMODE — Internal. Only to be used through TI provided API.
    1=CONT (Internal. Only to be used through TI provided API.); 0=SINGLE (Internal. Only to be used through TI provided API.)
  [2:1] ACCPERIOD — Internal. Only to be used through TI provided API.
    3=SMPL512 (Internal. Only to be used through TI provided API.); 2=SMPL128 (Internal. Only to be used through TI provided API.); 1=SMPL32 (Internal. Only to be used through TI provided API.); 0=SMPL8 (Internal. Only to be used through TI provided API.)
  [0] ACCEN — Internal. Only to be used through TI provided API.
    values as STRB0.MLSETERM
0x100 DEMFIDC0 — Internal. Only to be used through TI provided API.
  [5:4] COMPSEL — Internal. Only to be used through TI provided API.
    2=ACC (Internal. Only to be used through TI provided API.); 0=MANUAL (Internal. Only to be used through TI provided API.)
  [3:2] ACCPERIOD — Internal. Only to be used through TI provided API.
    values as DEMCODC0.ACCPERIOD
  [1] ACCMODE — Internal. Only to be used through TI provided API.
    values as DEMCODC0.ACCMODE
  [0] ACCEN — Internal. Only to be used through TI provided API.
    values as STRB0.MLSETERM
